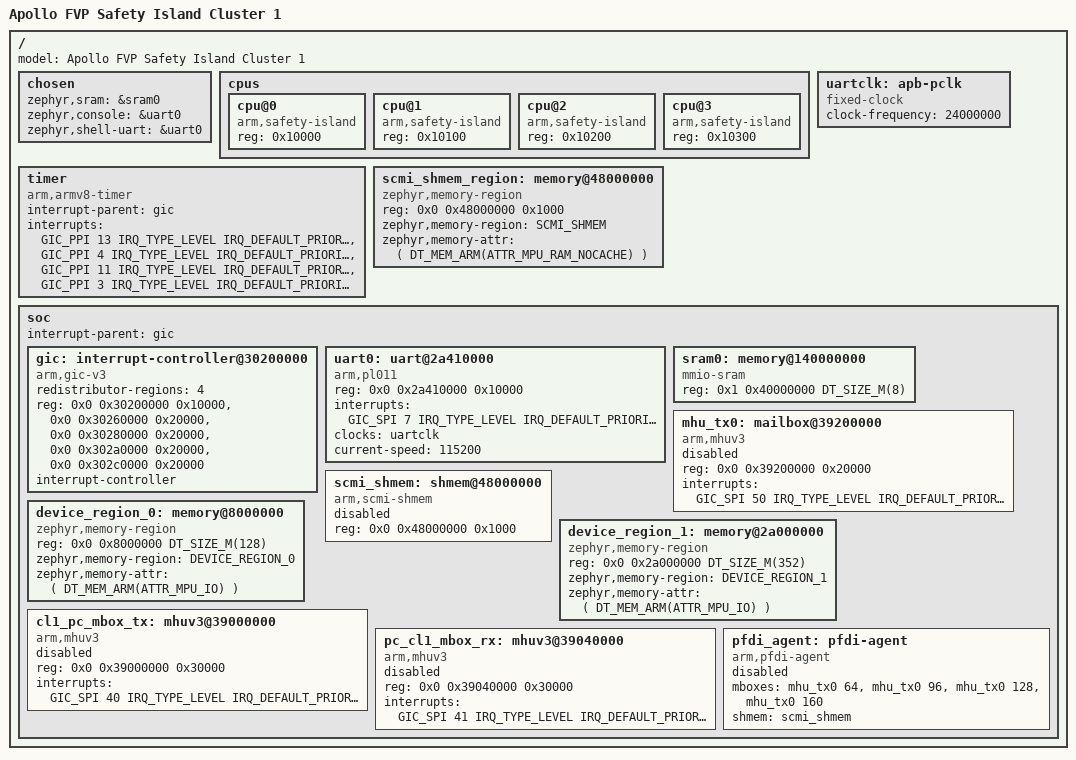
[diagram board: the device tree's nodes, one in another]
/*
 * SPDX-FileCopyrightText: <text>Copyright 2025-2026 Arm Limited and/or its
 * affiliates <open-source-office@arm.com></text>
 *
 * SPDX-License-Identifier: Apache-2.0
 */

/dts-v1/;

#include <mem.h>
#include <arm64/armv8-r.dtsi>
#include <dt-bindings/interrupt-controller/arm-gic.h>
#include <zephyr/dt-bindings/memory-attr/memory-attr-arm.h>

/ {
	#address-cells = <2>;
	#size-cells = <1>;
	model = "Apollo FVP Safety Island Cluster 1";

	chosen {
		zephyr,sram = &sram0;
		zephyr,console = &uart0;
		zephyr,shell-uart = &uart0;
	};

	cpus {
		#address-cells = <1>;
		#size-cells = <0>;

		cpu@0 {
			device_type = "cpu";
			compatible = "arm,safety-island";
			reg = <0x10000>;
		};

		cpu@1 {
			device_type = "cpu";
			compatible = "arm,safety-island";
			reg = <0x10100>;
		};

		cpu@2 {
			device_type = "cpu";
			compatible = "arm,safety-island";
			reg = <0x10200>;
		};

		cpu@3 {
			device_type = "cpu";
			compatible = "arm,safety-island";
			reg = <0x10300>;
		};

	};

	timer {
		compatible = "arm,armv8-timer";
		interrupt-parent = <&gic>;
		interrupts = <GIC_PPI 13 IRQ_TYPE_LEVEL
			      IRQ_DEFAULT_PRIORITY>,
			      <GIC_PPI 4 IRQ_TYPE_LEVEL
			      IRQ_DEFAULT_PRIORITY>,
			      <GIC_PPI 11 IRQ_TYPE_LEVEL
			      IRQ_DEFAULT_PRIORITY>,
			      <GIC_PPI 3 IRQ_TYPE_LEVEL
			      IRQ_DEFAULT_PRIORITY>;
	};

	uartclk: apb-pclk {
		compatible = "fixed-clock";
		clock-frequency = <24000000>;
		#clock-cells = <0>;
	};

	scmi_shmem_region: memory@48000000 {
		compatible = "zephyr,memory-region", "mmio-sram";
		reg = <0x0 0x48000000 0x1000>;
		zephyr,memory-region = "SCMI_SHMEM";
		zephyr,memory-attr = <( DT_MEM_ARM(ATTR_MPU_RAM_NOCACHE) )>;
	};

	soc {
		#address-cells = <2>;
		#size-cells = <1>;
		interrupt-parent = <&gic>;

		gic: interrupt-controller@30200000 {
			compatible = "arm,gic-v3", "arm,gic";
			redistributor-regions = <4>;
			reg = <0x0 0x30200000 0x10000>,   /* GICD */
			      <0x0 0x30260000 0x20000>,   /* GICR - CPU 0 */
			      <0x0 0x30280000 0x20000>,   /* GICR - CPU 1 */
			      <0x0 0x302a0000 0x20000>,   /* GICR - CPU 2 */
			      <0x0 0x302c0000 0x20000>;   /* GICR - CPU 3 */
			interrupt-controller;
			#interrupt-cells = <4>;
			status = "okay";
		};

		uart0: uart@2a410000 {
			compatible = "arm,pl011";
			reg = <0x0 0x2a410000 0x10000>;
			status = "disabled";
			interrupts = <GIC_SPI 7 IRQ_TYPE_LEVEL IRQ_DEFAULT_PRIORITY>;
			interrupt-names = "irq_0";
			clocks = <&uartclk>;
		};

		sram0: memory@140000000 {
			compatible = "mmio-sram";
			reg = <0x1 0x40000000 DT_SIZE_M(8)>;
		};

		/* MHUv3 Transmit for PFDI Agent */
		mhu_tx0: mailbox@39200000 {
			compatible = "arm,mhuv3";
			reg = <0x0 0x39200000 0x20000>;
			interrupts = <GIC_SPI 50 IRQ_TYPE_LEVEL IRQ_DEFAULT_PRIORITY>;
			interrupt-names = "combined";
			#mbox-cells = <1>;
			status = "disabled";
		};

		/* Shared Memory for SCMI */
		scmi_shmem: shmem@48000000 {
			compatible = "arm,scmi-shmem";
			reg = <0x0 0x48000000 0x1000>;
			status = "disabled";
		};

		device_region_0: memory@8000000 {
			compatible = "zephyr,memory-region", "mmio-sram";
			reg = <0x0 0x8000000 DT_SIZE_M(128)>;
			zephyr,memory-region = "DEVICE_REGION_0";
			zephyr,memory-attr = <( DT_MEM_ARM(ATTR_MPU_IO) )>;
		};

		device_region_1: memory@2a000000 {
			compatible = "zephyr,memory-region", "mmio-sram";
			reg = <0x0 0x2a000000 DT_SIZE_M(352)>;
			zephyr,memory-region = "DEVICE_REGION_1";
			zephyr,memory-attr = <( DT_MEM_ARM(ATTR_MPU_IO) )>;
		};

		cl1_pc_mbox_tx: mhuv3@39000000 {
			compatible = "arm,mhuv3";
			#mbox-cells = <1>;
			reg = <0x0 0x39000000 0x30000>;
			interrupts = <GIC_SPI 40 IRQ_TYPE_LEVEL IRQ_DEFAULT_PRIORITY>;
			interrupt-names = "combined";
			status = "disabled";
		};

		pc_cl1_mbox_rx: mhuv3@39040000 {
			compatible = "arm,mhuv3";
			#mbox-cells = <1>;
			reg = <0x0 0x39040000 0x30000>;
			interrupts = <GIC_SPI 41 IRQ_TYPE_LEVEL IRQ_DEFAULT_PRIORITY>;
			interrupt-names = "combined";
			status = "disabled";
		};

		/* PFDI Agent - sends status to Cluster 0 */
		pfdi_agent: pfdi-agent {
			compatible = "arm,pfdi-agent";
			mboxes = <&mhu_tx0 64>, <&mhu_tx0 96>,
				 <&mhu_tx0 128>, <&mhu_tx0 160>;
			shmem = <&scmi_shmem>;
			status = "disabled";
		};
	};
};

&uart0 {
	status = "okay";
	current-speed = <115200>;
};
